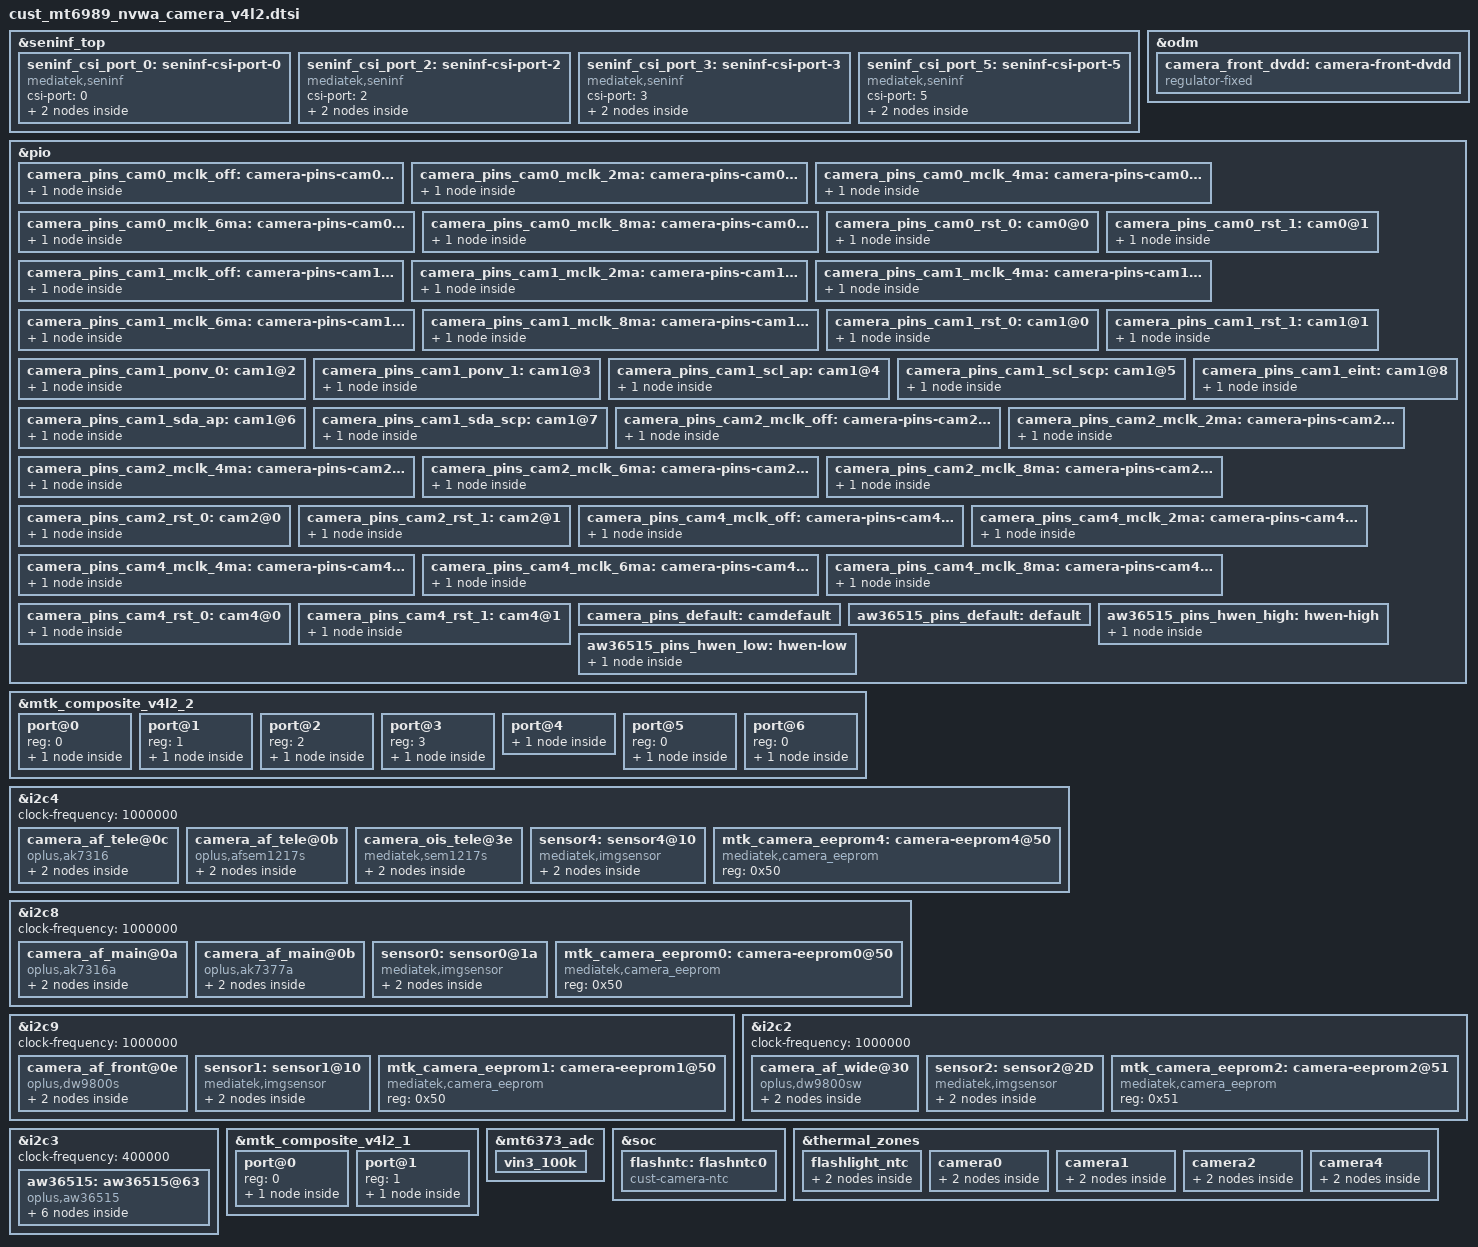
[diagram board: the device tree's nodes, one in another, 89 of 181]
// SPDX-License-Identifier: GPL-2.0
/* Copyright (c) 2023 MediaTek Inc. */
#include <dt-bindings/clock/mt6989-clk.h>
#include "mediatek/nvwa_regulator.dtsi"
&seninf_top {
		seninf_csi_port_0: seninf-csi-port-0 {
			compatible = "mediatek,seninf";
			csi-port = "0";
#if 0
			nvmem-cells = <&csi_efuse0>;
			nvmem-cell-names = "rg_csi";
#endif
			port {
				seninf_csi_port_0_in: endpoint {
					remote-endpoint = <&sensor4_out>;
				};
			};
		};

		seninf_csi_port_2: seninf-csi-port-2 {
			compatible = "mediatek,seninf";
			csi-port = "2";
#if 0
			nvmem-cells = <&csi_efuse2>;
			nvmem-cell-names = "rg_csi";
#endif
			port {
				seninf_csi_port_2_in: endpoint {
					remote-endpoint = <&sensor0_out>;
				};
			};
		};

		seninf_csi_port_3: seninf-csi-port-3 {
			compatible = "mediatek,seninf";
			csi-port = "3";
#if 0
			nvmem-cells = <&csi_efuse3>;
			nvmem-cell-names = "rg_csi";
#endif
			port {
				seninf_csi_port_3_in: endpoint {
					remote-endpoint = <&sensor2_out>;
				};
			};
		};

		seninf_csi_port_5: seninf-csi-port-5 {
			compatible = "mediatek,seninf";
			csi-port = "5";
#if 0
			nvmem-cells = <&csi_efuse5>;
			nvmem-cell-names = "rg_csi";
#endif
			port {
				seninf_csi_port_5_in: endpoint {
					remote-endpoint = <&sensor1_out>;
				};
			};
		};
};

/* CAMERA GPIO fixed to regulator */
&odm {
	camera_front_dvdd: camera-front-dvdd {
		compatible = "regulator-fixed";
		regulator-name = "camera-front-dvdd";
		regulator-min-microvolt = <816000>;
		regulator-max-microvolt = <816000>;
		enable-active-high;
		gpio = <&pio 94 0x0>;
	};
};

/* CAMERA GPIO standardization */
&pio {
	camera_pins_cam0_mclk_off: camera-pins-cam0-mclk-off {
		pins-cmd-dat {
			pinmux = <PINMUX_GPIO117__FUNC_GPIO117>;
			drive-strength = <1>;
		};
	};
	camera_pins_cam0_mclk_2ma: camera-pins-cam0-mclk-2ma {
		pins-cmd-dat {
			pinmux = <PINMUX_GPIO117__FUNC_CMMCLK3>;
			drive-strength = <0>;
		};
	};
	camera_pins_cam0_mclk_4ma: camera-pins-cam0-mclk-4ma {
		pins-cmd-dat {
			pinmux = <PINMUX_GPIO117__FUNC_CMMCLK3>;
			drive-strength = <1>;
		};
	};
	camera_pins_cam0_mclk_6ma: camera-pins-cam0-mclk-6ma {
		pins-cmd-dat {
			pinmux = <PINMUX_GPIO117__FUNC_CMMCLK3>;
			drive-strength = <2>;
		};
	};
	camera_pins_cam0_mclk_8ma: camera-pins-cam0-mclk-8ma {
		pins-cmd-dat {
			pinmux = <PINMUX_GPIO117__FUNC_CMMCLK3>;
			drive-strength = <3>;
		};
	};
	camera_pins_cam0_rst_0: cam0@0 {
		pins-cmd-dat {
			pinmux = <PINMUX_GPIO118__FUNC_GPIO118>;
			slew-rate = <1>;
			output-low;
		};
	};
	camera_pins_cam0_rst_1: cam0@1 {
		pins-cmd-dat {
			pinmux = <PINMUX_GPIO118__FUNC_GPIO118>;
			slew-rate = <1>;
			output-high;
		};
	};
	camera_pins_cam1_mclk_off: camera-pins-cam1-mclk-off {
		pins-cmd-dat {
			pinmux = <PINMUX_GPIO124__FUNC_GPIO124>;
			drive-strength = <1>;
		};
	};
	camera_pins_cam1_mclk_2ma: camera-pins-cam1-mclk-2ma {
		pins-cmd-dat {
			pinmux = <PINMUX_GPIO124__FUNC_CMMCLK0>;
			drive-strength = <0>;
		};
	};
	camera_pins_cam1_mclk_4ma: camera-pins-cam1-mclk-4ma {
		pins-cmd-dat {
			pinmux = <PINMUX_GPIO124__FUNC_CMMCLK0>;
			drive-strength = <1>;
		};
	};
	camera_pins_cam1_mclk_6ma: camera-pins-cam1-mclk-6ma {
		pins-cmd-dat {
			pinmux = <PINMUX_GPIO124__FUNC_CMMCLK0>;
			drive-strength = <2>;
		};
	};
	camera_pins_cam1_mclk_8ma: camera-pins-cam1-mclk-8ma {
		pins-cmd-dat {
			pinmux = <PINMUX_GPIO124__FUNC_CMMCLK0>;
			drive-strength = <3>;
		};
	};
	camera_pins_cam1_rst_0: cam1@0 {
		pins-cmd-dat {
			pinmux = <PINMUX_GPIO16__FUNC_GPIO16>;
			slew-rate = <1>;
			output-low;
		};
	};
	camera_pins_cam1_rst_1: cam1@1 {
		pins-cmd-dat {
			pinmux = <PINMUX_GPIO16__FUNC_GPIO16>;
			slew-rate = <1>;
			output-high;
		};
	};
	camera_pins_cam1_ponv_0: cam1@2 {
		pins-cmd-dat {
			pinmux = <PINMUX_GPIO17__FUNC_GPIO17>;
			slew-rate = <1>;
			output-low;
		};
	};
	camera_pins_cam1_ponv_1: cam1@3 {
		pins-cmd-dat {
			pinmux = <PINMUX_GPIO17__FUNC_GPIO17>;
			slew-rate = <1>;
			output-high;
		};
	};
	camera_pins_cam1_scl_ap: cam1@4 {
		pins-cmd-dat {
			pinmux = <PINMUX_GPIO102__FUNC_SCL9>;
		};
	};
	camera_pins_cam1_scl_scp: cam1@5 {
		pins-cmd-dat {
			pinmux = <PINMUX_GPIO102__FUNC_SCP_SCL7>;
		};
	};
	camera_pins_cam1_sda_ap: cam1@6 {
		pins-cmd-dat {
			pinmux = <PINMUX_GPIO103__FUNC_SDA9>;
		};
	};
	camera_pins_cam1_sda_scp: cam1@7 {
		pins-cmd-dat {
			pinmux = <PINMUX_GPIO103__FUNC_SCP_SDA7>;
		};
	};
	camera_pins_cam1_eint: cam1@8 {
		pins-cmd-dat {
			pinmux = <PINMUX_GPIO113__FUNC_GPIO113>;
			bias-pull-up;
			input-enable;
		};
	};
	camera_pins_cam2_mclk_off: camera-pins-cam2-mclk-off {
		pins-cmd-dat {
			pinmux = <PINMUX_GPIO116__FUNC_GPIO116>;
			drive-strength = <1>;
		};
	};
	camera_pins_cam2_mclk_2ma: camera-pins-cam2-mclk-2ma {
		pins-cmd-dat {
			pinmux = <PINMUX_GPIO116__FUNC_CMMCLK2>;
			drive-strength = <0>;
		};
	};
	camera_pins_cam2_mclk_4ma: camera-pins-cam2-mclk-4ma {
		pins-cmd-dat {
			pinmux = <PINMUX_GPIO116__FUNC_CMMCLK2>;
			drive-strength = <1>;
		};
	};
	camera_pins_cam2_mclk_6ma: camera-pins-cam2-mclk-6ma {
		pins-cmd-dat {
			pinmux = <PINMUX_GPIO116__FUNC_CMMCLK2>;
			drive-strength = <2>;
		};
	};
	camera_pins_cam2_mclk_8ma: camera-pins-cam2-mclk-8ma {
		pins-cmd-dat {
			pinmux = <PINMUX_GPIO116__FUNC_CMMCLK2>;
			drive-strength = <3>;
		};
	};
	camera_pins_cam2_rst_0: cam2@0 {
		pins-cmd-dat {
			pinmux = <PINMUX_GPIO119__FUNC_GPIO119>;
			slew-rate = <1>;
			output-low;
		};
	};
	camera_pins_cam2_rst_1: cam2@1 {
		pins-cmd-dat {
			pinmux = <PINMUX_GPIO119__FUNC_GPIO119>;
			slew-rate = <1>;
			output-high;
		};
	};

	camera_pins_cam4_mclk_off: camera-pins-cam4-mclk-off {
		pins-cmd-dat {
			pinmux = <PINMUX_GPIO125__FUNC_GPIO125>;
			drive-strength = <1>;
		};
	};
	camera_pins_cam4_mclk_2ma: camera-pins-cam4-mclk-2ma {
		pins-cmd-dat {
			pinmux = <PINMUX_GPIO125__FUNC_CMMCLK1>;
			drive-strength = <0>;
		};
	};
	camera_pins_cam4_mclk_4ma: camera-pins-cam4-mclk-4ma {
		pins-cmd-dat {
			pinmux = <PINMUX_GPIO125__FUNC_CMMCLK1>;
			drive-strength = <1>;
		};
	};
	camera_pins_cam4_mclk_6ma: camera-pins-cam4-mclk-6ma {
		pins-cmd-dat {
			pinmux = <PINMUX_GPIO125__FUNC_CMMCLK1>;
			drive-strength = <2>;
		};
	};
	camera_pins_cam4_mclk_8ma: camera-pins-cam4-mclk-8ma {
		pins-cmd-dat {
			pinmux = <PINMUX_GPIO125__FUNC_CMMCLK1>;
			drive-strength = <3>;
		};
	};
	camera_pins_cam4_rst_0: cam4@0 {
		pins-cmd-dat {
			pinmux = <PINMUX_GPIO110__FUNC_GPIO110>;
			slew-rate = <1>;
			output-low;
		};
	};
	camera_pins_cam4_rst_1: cam4@1 {
		pins-cmd-dat {
			pinmux = <PINMUX_GPIO110__FUNC_GPIO110>;
			slew-rate = <1>;
			output-high;
		};
	};

	camera_pins_default: camdefault {
	};
};
/* CAMERA GPIO end */

&mtk_composite_v4l2_2 {

	#address-cells = <1>;
	#size-cells = <0>;

	port@0 {
		reg = <0>;
		main_af_endpoint: endpoint {
			remote-endpoint = <&main_af>;
		};
	};
	port@1 {
		reg = <1>;
		front_af_endpoint: endpoint {
			remote-endpoint = <&front_af>;
		};
	};
	port@2 {
		reg = <2>;
		wide_af_endpoint: endpoint {
			remote-endpoint = <&wide_af>;
		};
	};
	port@3 {
		reg = <3>;
		tele_af_endpoint: endpoint {
			remote-endpoint = <&tele_af>;
		};
	};
	port@4 {
		tele_ois_endpoint: endpoint {
			remote-endpoint = <&tele_ois>;
		};
	};
	port@5 {
		reg = <0>;
		main_af2_endpoint: endpoint {
			remote-endpoint = <&main_af2>;
		};
	};
	port@6 {
		reg = <0>;
		tele_af2_endpoint: endpoint {
			remote-endpoint = <&tele_af2>;
		};
	};
};

&i2c4 {
	status = "okay";
	clock-frequency = <1000000>;
	#address-cells = <1>;
	#size-cells = <0>;

	camera_af_tele@0c {
		compatible = "oplus,ak7316";
		reg = <0x0c>;
		vin-supply = <&wl28681c1_ldo7a>;
		port {
			tele_af: endpoint {
				remote-endpoint = <&tele_af_endpoint>;
			};
		};
	};

	camera_af_tele@0b {
		compatible = "oplus,afsem1217s";
		reg = <0x0b>;
		vin-supply = <&wl28681c1_ldo7a>;
		vdd-supply = <&wl28681c1_ldo6a>;
		avdd-supply = <&wl28681c1_ldo5a>;
		port {
			tele_af2: endpoint {
				remote-endpoint = <&tele_af2_endpoint>;
			};
		};
	};

	camera_ois_tele@3e {
		compatible = "mediatek,sem1217s";
		reg = <0x3e>;
		iovdd-supply = <&wl28681c1_ldo6a>;
		avdd-supply = <&wl28681c1_ldo5a>;
		port {
			tele_ois: endpoint {
				remote-endpoint = <&tele_ois_endpoint>;
			};
		};
	};

	sensor4: sensor4@10 {
		compatible = "mediatek,imgsensor";
		sensor-names = "nvwaearth_mipi_raw","nvwatele_mipi_raw";
		reg = <0x10>;
		#thermal-sensor-cells = <0>;

		pinctrl-names = "mclk_off",
				"mclk_2mA",
				"mclk_4mA",
				"mclk_6mA",
				"mclk_8mA",
				"rst_low",
				"rst_high";
		pinctrl-0 = <&camera_pins_cam4_mclk_off>;
		pinctrl-1 = <&camera_pins_cam4_mclk_2ma>;
		pinctrl-2 = <&camera_pins_cam4_mclk_4ma>;
		pinctrl-3 = <&camera_pins_cam4_mclk_6ma>;
		pinctrl-4 = <&camera_pins_cam4_mclk_8ma>;
		pinctrl-5 = <&camera_pins_cam4_rst_0>;
		pinctrl-6 = <&camera_pins_cam4_rst_1>;

		avdd-supply = <&wl28681c1_ldo4a>;
		avdd1-supply = <&wl28681c1_ldo5a>;
		dvdd-supply = <&wl28681c1_ldo2a>;
		dovdd-supply = <&wl28681c1_ldo6a>;
		afvdd-supply = <&wl28681c1_ldo7a>;

		clocks = <&topckgen_clk CLK_TOP_UNIVPLL2_192M_D32>,
			<&topckgen_clk CLK_TOP_UNIVPLL2_192M_D16>,
			<&topckgen_clk CLK_TOP_F26M_CK_D2>,
			<&topckgen_clk CLK_TOP_UNIVPLL2_192M_D10>,
			<&topckgen_clk CLK_TOP_UNIVPLL2_192M_D8>,
			<&topckgen_clk CLK_TOP_UNIVPLL2_D6_D16>,
			<&topckgen_clk CLK_TOP_UNIVPLL2_D6_D8>,
			<&topckgen_clk CLK_TOP_CAMTG1_SEL>;
		clock-names = "6", "12", "13", "19.2", "24", "26", "52", "mclk";

		status = "okay";

		port {
			sensor4_out: endpoint {
				remote-endpoint = <&seninf_csi_port_0_in>;
			};
		};
	};

	mtk_camera_eeprom4:camera-eeprom4@50 {
		compatible = "mediatek,camera_eeprom";
		reg = <0x50>;
		status = "okay";
	};
};

&i2c8 {
	status = "okay";
	clock-frequency = <1000000>;
	#address-cells = <1>;
	#size-cells = <0>;

	camera_af_main@0a {
		compatible = "oplus,ak7316a";
		reg = <0x0a>;
		vin-supply = <&wl28681c2_ldo7a>;
		port {
			main_af: endpoint {
				remote-endpoint = <&main_af_endpoint>;
			};
		};
	};

	camera_af_main@0b {
		compatible = "oplus,ak7377a";
		reg = <0x0b>;
		vin-supply = <&wl28681c2_ldo7a>;
		port {
			main_af2: endpoint {
				remote-endpoint = <&main_af2_endpoint>;
			};
		};
	};

	sensor0: sensor0@1a {
		compatible = "mediatek,imgsensor";
		sensor-names = "nvwamain_mipi_raw","nvwasun2_mipi_raw";
		reg = <0x1a>;
		pinctrl-names = "mclk_off",
				"mclk_2mA",
				"mclk_4mA",
				"mclk_6mA",
				"mclk_8mA",
				"rst_low",
				"rst_high";
		pinctrl-0 = <&camera_pins_cam0_mclk_off>;
		pinctrl-1 = <&camera_pins_cam0_mclk_2ma>;
		pinctrl-2 = <&camera_pins_cam0_mclk_4ma>;
		pinctrl-3 = <&camera_pins_cam0_mclk_6ma>;
		pinctrl-4 = <&camera_pins_cam0_mclk_8ma>;
		pinctrl-5 = <&camera_pins_cam0_rst_0>;
		pinctrl-6 = <&camera_pins_cam0_rst_1>;

		avdd1-supply = <&wl28681c2_ldo5a>;
		avdd-supply = <&wl28681c2_ldo4a>;
		dvdd-supply = <&wl28681c2_ldo1a>;
		dovdd-supply = <&wl28681c1_ldo6a>;
		afvdd-supply = <&wl28681c2_ldo7a>;

		clocks = <&topckgen_clk CLK_TOP_UNIVPLL2_192M_D32>,
			<&topckgen_clk CLK_TOP_UNIVPLL2_192M_D16>,
			<&topckgen_clk CLK_TOP_F26M_CK_D2>,
			<&topckgen_clk CLK_TOP_UNIVPLL2_192M_D10>,
			<&topckgen_clk CLK_TOP_UNIVPLL2_192M_D8>,
			<&topckgen_clk CLK_TOP_UNIVPLL2_D6_D16>,
			<&topckgen_clk CLK_TOP_UNIVPLL2_D6_D8>,
			<&topckgen_clk CLK_TOP_CAMTG3_SEL>;
		clock-names = "6", "12", "13", "19.2", "24", "26", "52", "mclk";

		status = "okay";

		port {
			sensor0_out: endpoint {
				remote-endpoint = <&seninf_csi_port_2_in>;
			};
		};
	};

	mtk_camera_eeprom0:camera-eeprom0@50 {
		compatible = "mediatek,camera_eeprom";
		reg = <0x50>;
		status = "okay";
	};
};

&i2c9 {
	status = "okay";
	clock-frequency = <1000000>;
	#address-cells = <1>;
	#size-cells = <0>;

	camera_af_front@0e {
		compatible = "oplus,dw9800s";
		reg = <0x0e>;
		vin-supply = <&wl28681c1_ldo7a>;
		port {
			front_af: endpoint {
				remote-endpoint = <&front_af_endpoint>;
			};
		};
	};

	sensor1: sensor1@10 {
		compatible = "mediatek,imgsensor";
		sensor-names = "nvwafront_mipi_raw","nvwafront2_mipi_raw";
		reg = <0x10>;
		#thermal-sensor-cells = <0>;

		pinctrl-names = "mclk1_off",
				"mclk1_2mA",
				"mclk1_4mA",
				"mclk1_6mA",
				"mclk1_8mA",
				"rst_low",
				"rst_high",
				"ponv_low",
				"ponv_high",
				"scl_ap",
				"scl_scp",
				"sda_ap",
				"sda_scp",
				"eint";

		pinctrl-0 = <&camera_pins_cam1_mclk_off>;
		pinctrl-1 = <&camera_pins_cam1_mclk_2ma>;
		pinctrl-2 = <&camera_pins_cam1_mclk_4ma>;
		pinctrl-3 = <&camera_pins_cam1_mclk_6ma>;
		pinctrl-4 = <&camera_pins_cam1_mclk_8ma>;
		pinctrl-5 = <&camera_pins_cam1_rst_0>;
		pinctrl-6 = <&camera_pins_cam1_rst_1>;
		pinctrl-7 = <&camera_pins_cam1_ponv_0>;
		pinctrl-8 = <&camera_pins_cam1_ponv_1>;
		pinctrl-9 = <&camera_pins_cam1_scl_ap>;
		pinctrl-10 = <&camera_pins_cam1_scl_scp>;
		pinctrl-11 = <&camera_pins_cam1_sda_ap>;
		pinctrl-12 = <&camera_pins_cam1_sda_scp>;
		pinctrl-13 = <&camera_pins_cam1_eint>;

		avdd-supply = <&wl28681c1_ldo3a>;
		dvdd-supply = <&camera_front_dvdd>;
		dovdd-supply = <&wl28681c1_ldo6a>;
		afvdd-supply = <&wl28681c1_ldo7a>;

		clocks =<&topckgen_clk CLK_TOP_UNIVPLL_192M_D32>,
			<&topckgen_clk CLK_TOP_UNIVPLL_192M_D16>,
			<&topckgen_clk CLK_TOP_F26M_CK_D2>,
			<&topckgen_clk CLK_TOP_UNIVPLL_192M_D10>,
			<&topckgen_clk CLK_TOP_UNIVPLL_192M_D8>,
			<&topckgen_clk CLK_TOP_UNIVPLL_D6_D16>,
			<&topckgen_clk CLK_TOP_OSC_D20>,
			<&topckgen_clk CLK_TOP_UNIVPLL_D6_D8>,
			<&vlp_cksys_clk CLK_VLP_CK_CAMTG0_SEL>;
		clock-names ="clk1_6", "clk1_12", "clk1_13", "clk1_19.2",
			      "clk1_24", "clk1_26", "clk1_26_ulposc", "clk1_52", "clk1_mclk1";

		status = "okay";
		port {
			sensor1_out: endpoint {
				remote-endpoint = <&seninf_csi_port_5_in>;
			};
		};
	};

	mtk_camera_eeprom1:camera-eeprom1@50 {
		compatible = "mediatek,camera_eeprom";
		reg = <0x50>;
		status = "okay";
	};
};

&i2c2 {
	status = "okay";
	clock-frequency = <1000000>;
	#address-cells = <1>;
	#size-cells = <0>;

	camera_af_wide@30 {
		compatible = "oplus,dw9800sw";
		reg = <0x30>;
		vin-supply = <&wl28681c2_ldo6a>;
		port {
			wide_af: endpoint {
				remote-endpoint = <&wide_af_endpoint>;
			};
		};
	};

	sensor2: sensor2@2D {
		compatible = "mediatek,imgsensor";
		sensor-names = "nvwauwide_mipi_raw","nvwamars_mipi_raw","nvwamars2_mipi_raw";
		reg = <0x2D>;
		#thermal-sensor-cells = <0>;

		pinctrl-names = "mclk_off",
				"mclk_2mA",
				"mclk_4mA",
				"mclk_6mA",
				"mclk_8mA",
				"rst_low",
				"rst_high";
		pinctrl-0 = <&camera_pins_cam2_mclk_off>;
		pinctrl-1 = <&camera_pins_cam2_mclk_2ma>;
		pinctrl-2 = <&camera_pins_cam2_mclk_4ma>;
		pinctrl-3 = <&camera_pins_cam2_mclk_6ma>;
		pinctrl-4 = <&camera_pins_cam2_mclk_8ma>;
		pinctrl-5 = <&camera_pins_cam2_rst_0>;
		pinctrl-6 = <&camera_pins_cam2_rst_1>;

		avdd-supply = <&wl28681c2_ldo3a>;
		avdd1-supply = <&wl28681c1_ldo5a>;
		dvdd-supply = <&wl28681c2_ldo2a>;
		dovdd-supply = <&wl28681c1_ldo6a>;
		afvdd-supply = <&wl28681c2_ldo6a>;

		clocks = <&topckgen_clk CLK_TOP_UNIVPLL2_192M_D32>,
			<&topckgen_clk CLK_TOP_UNIVPLL2_192M_D16>,
			<&topckgen_clk CLK_TOP_F26M_CK_D2>,
			<&topckgen_clk CLK_TOP_UNIVPLL2_192M_D10>,
			<&topckgen_clk CLK_TOP_UNIVPLL2_192M_D8>,
			<&topckgen_clk CLK_TOP_UNIVPLL2_D6_D16>,
			<&topckgen_clk CLK_TOP_UNIVPLL2_D6_D8>,
			<&topckgen_clk CLK_TOP_CAMTG2_SEL>;
		clock-names = "6", "12", "13", "19.2", "24", "26", "52", "mclk";

		status = "okay";

		port {
			sensor2_out: endpoint {
				remote-endpoint = <&seninf_csi_port_3_in>;
			};
		};
	};

	mtk_camera_eeprom2:camera-eeprom2@51 {
		compatible = "mediatek,camera_eeprom";
		reg = <0x51>;
		status = "okay";
	};
};

&i2c3 {
	clock-frequency = <400000>;
	#address-cells = <1>;
	#size-cells = <0>;
	aw36515:aw36515@63 {
		compatible = "oplus,aw36515";
		#address-cells = <1>;
		#size-cells = <0>;
		reg = <0x63>;
		#cooling-cells = <2>;
		pinctrl-names = "default", "hwen-high", "hwen-low";
		pinctrl-0 = <&aw36515_pins_default>;
		pinctrl-1 = <&aw36515_pins_hwen_high>;
		pinctrl-2 = <&aw36515_pins_hwen_low>;
		status = "okay";
		flash@0{
			reg = <0>;
			type = <0>;
			ct = <0>;
			part = <0>;
			port {
				fl_core_0: endpoint {
					remote-endpoint = <&flashlight_0>;
				};
			};
		};
		flash@1{
			reg = <1>;
			type = <0>;
			ct = <1>;
			part = <0>;
			port {
				fl_core_1: endpoint {
					remote-endpoint = <&flashlight_1>;
				};
			};
		};
	};
};

&pio {
	aw36515_pins_default: default {
	};

	aw36515_pins_hwen_high: hwen-high {
		pins_cmd_dat {
			pinmux = <PINMUX_GPIO70__FUNC_GPIO70>;
			slew-rate = <1>;
			output-high;
		};
	};

	aw36515_pins_hwen_low: hwen-low {
		pins_cmd_dat {
			pinmux = <PINMUX_GPIO70__FUNC_GPIO70>;
			slew-rate = <1>;
			output-low;
		};
	};
};

&mtk_composite_v4l2_1 {
	#address-cells = <1>;
	#size-cells = <0>;
	port@0 {
		reg = <0>;
		flashlight_0: endpoint {
			remote-endpoint = <&fl_core_0>;
		};
	};
	port@1 {
		reg = <1>;
		flashlight_1: endpoint {
			remote-endpoint = <&fl_core_1>;
		};
	};
};

&mt6373_adc {
	vin3_100k {
		channel = <AUXADC_VIN3>;
		pures = <ADC_PURES_100K>;
	};
};

&soc {
	flashntc: flashntc0 {
		compatible = "cust-camera-ntc";
		#thermal-sensor-cells = <0>;
		io-channels = <&mt6373_adc (ADC_PURES_100K_MASK | AUXADC_VIN3)>;
		io-channel-names = "sensor-channel";
		temperature-lookup-table =
			<(-40000) 1799>,
			<(-39000) 1796>,
			<(-38000) 1793>,
			<(-37000) 1790>,
			<(-36000) 1786>,
			<(-35000) 1782>,
			<(-34000) 1778>,
			<(-33000) 1774>,
			<(-32000) 1770>,
			<(-31000) 1765>,
			<(-30000) 1760>,
			<(-29000) 1755>,
			<(-28000) 1749>,
			<(-27000) 1743>,
			<(-26000) 1737>,
			<(-25000) 1731>,
			<(-24000) 1724>,
			<(-23000) 1717>,
			<(-22000) 1709>,
			<(-21000) 1701>,
			<(-20000) 1693>,
			<(-19000) 1684>,
			<(-18000) 1675>,
			<(-17000) 1666>,
			<(-16000) 1656>,
			<(-15000) 1646>,
			<(-14000) 1635>,
			<(-13000) 1624>,
			<(-12000) 1612>,
			<(-11000) 1600>,
			<(-10000) 1588>,
			<(-9000) 1575>,
			<(-8000) 1562>,
			<(-7000) 1548>,
			<(-6000) 1533>,
			<(-5000) 1519>,
			<(-4000) 1503>,
			<(-3000) 1488>,
			<(-2000) 1472>,
			<(-1000) 1455>,
			<0 1438>,
			<1000 1421>,
			<2000 1403>,
			<3000 1385>,
			<4000 1366>,
			<5000 1347>,
			<6000 1328>,
			<7000 1308>,
			<8000 1289>,
			<9000 1268>,
			<10000 1248>,
			<11000 1227>,
			<12000 1206>,
			<13000 1185>,
			<14000 1164>,
			<15000 1142>,
			<16000 1120>,
			<17000 1099>,
			<18000 1077>,
			<19000 1055>,
			<20000 1033>,
			<21000 1011>,
			<22000 990>,
			<23000 968>,
			<24000 946>,
			<25000 925>,
			<26000 903>,
			<27000 882>,
			<28000 861>,
			<29000 840>,
			<30000 819>,
			<31000 799>,
			<32000 778>,
			<33000 758>,
			<34000 739>,
			<35000 719>,
			<36000 700>,
			<37000 681>,
			<38000 663>,
			<39000 645>,
			<40000 627>,
			<41000 609>,
			<42000 592>,
			<43000 576>,
			<44000 559>,
			<45000 543>,
			<46000 528>,
			<47000 512>,
			<48000 498>,
			<49000 483>,
			<50000 469>,
			<51000 455>,
			<52000 442>,
			<53000 429>,
			<54000 416>,
			<55000 404>,
			<56000 392>,
			<57000 380>,
			<58000 368>,
			<59000 357>,
			<60000 347>,
			<61000 336>,
			<62000 326>,
			<63000 317>,
			<64000 307>,
			<65000 298>,
			<66000 289>,
			<67000 280>,
			<68000 272>,
			<69000 264>,
			<70000 256>,
			<71000 249>,
			<72000 241>,
			<73000 234>,
			<74000 227>,
			<75000 221>,
			<76000 214>,
			<77000 208>,
			<78000 202>,
			<79000 196>,
			<80000 191>,
			<81000 185>,
			<82000 180>,
			<83000 175>,
			<84000 170>,
			<85000 165>,
			<86000 161>,
			<87000 156>,
			<88000 152>,
			<89000 148>,
			<90000 144>,
			<91000 140>,
			<92000 136>,
			<93000 133>,
			<94000 129>,
			<95000 126>,
			<96000 122>,
			<97000 119>,
			<98000 116>,
			<99000 113>,
			<100000 110>,
			<101000 108>,
			<102000 105>,
			<103000 102>,
			<104000 100>,
			<105000 97>,
			<106000 95>,
			<107000 93>,
			<108000 91>,
			<109000 89>,
			<110000 87>,
			<111000 85>,
			<112000 83>,
			<113000 81>,
			<114000 79>,
			<115000 77>,
			<116000 76>,
			<117000 74>,
			<118000 72>,
			<119000 71>,
			<120000 69>,
			<121000 68>,
			<122000 67>,
			<123000 65>,
			<124000 64>,
			<125000 63>;
	};
};

&thermal_zones {
	flashlight_ntc: flashlight_ntc {
		polling-delay = <0>; /* milliseconds */
		polling-delay-passive = <0>; /* milliseconds */
		thermal-sensors = <&flashntc>;
		trips {
			flashlight_ntc_crit: flashlight_ntc-crit {
				temperature = <120000>;
				hysteresis = <2000>;
				type = "passive";
			};
		};
	};

	camera0: camera0 {
		polling-delay = <0>; /* milliseconds */
		polling-delay-passive = <0>; /* milliseconds */
		thermal-sensors = <&sensor0>;
		trips {
			camera0_crit: camera0-crit {
				temperature = <120000>;
				hysteresis = <2000>;
				type = "passive";
			};
		};
	};
	camera1: camera1 {
		polling-delay = <0>; /* milliseconds */
		polling-delay-passive = <0>; /* milliseconds */
		thermal-sensors = <&sensor1>;
		trips {
			camera1_crit: camera1-crit {
				temperature = <120000>;
				hysteresis = <2000>;
				type = "passive";
			};
		};
	};
	camera2: camera2 {
		polling-delay = <0>; /* milliseconds */
		polling-delay-passive = <0>; /* milliseconds */
		thermal-sensors = <&sensor2>;
		trips {
			camera2_crit: camera2-crit {
				temperature = <120000>;
				hysteresis = <2000>;
				type = "passive";
			};
		};
	};
	camera4: camera4 {
		polling-delay = <0>; /* milliseconds */
		polling-delay-passive = <0>; /* milliseconds */
		thermal-sensors = <&sensor4>;
		trips {
			camera4_crit: camera4-crit {
				temperature = <120000>;
				hysteresis = <2000>;
				type = "passive";
			};
		};
	};
};
